# R7FA8M1AH register map
Vendor: Renesas; Series: RA8; File version: 1.2
CPU: CM85 r0p0, little endian, MPU, FPU, VTOR, 4 interrupt priority bits
Registers are 32-bit, read-write, reset 0x0 unless marked. A register's access mark holds for its fields unless they carry their own. Offsets are from the block's base; [hi:lo] are bit positions; {n}, {i} and the like mark numbered series; 'fields as' and 'values as' point back to an identical list.

## CANFD0 (part 1 of 2) — CANFD Module 0
Base 0x40380000
Same registers: CANFD1 0x40382000, CANFD0_NS 0x50380000, CANFD1_NS 0x50382000
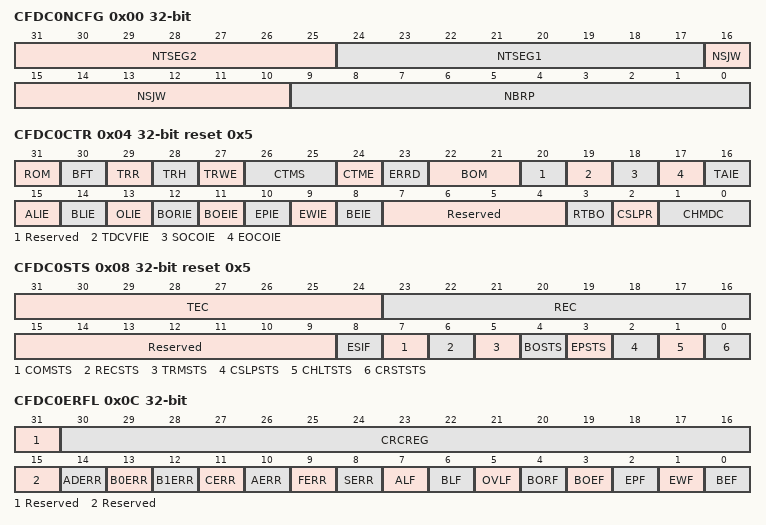
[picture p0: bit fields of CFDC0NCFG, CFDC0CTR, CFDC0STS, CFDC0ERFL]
0x00 CFDC0NCFG — Channel 0 Nominal Bitrate Configuration Register
  [31:25] NTSEG2 — Timing Segment 2
    1=2Tq; 2=3Tq; 3=4Tq; 126=127 Tq; 127=128 Tq
  [24:17] NTSEG1 — Timing Segment 1
    1=2Tq; 2=3Tq; 3=4Tq; 254=255 Tq; 255=256 Tq
  [16:10] NSJW — Resynchronization Jump Width
    {v}={v+1}Tq (v=0..3); 126=127 Tq; 127=128 Tq
  [9:0] NBRP — Channel Nominal Baud Rate Prescaler
0x04 CFDC0CTR reset 0x5 — Channel 0 Control Registers
  [31] ROM — Restricted Operation Mode
    0=Restricted Operation Mode disabled; 1=Restricted Operation Mode enabled
  [30] BFT — Bit Flip Test
    0=First data bit of reception stream not inverted; 1=First data bit of reception stream inverted
  [29] TRR — TEC/REC Reset
    0=Error counter normal operation; 1=Error counter reset
  [28] TRH — TEC/REC Hold
    0=Error counter normal operation; 1=Error counter frozen
  [27] TRWE — TEC/REC Write Enable
    0=Error Counter write disabled; 1=Error Counter write enabled
  [26:25] CTMS — Channel Test Mode Select
    0=Basic test mode; 1=Listen-Only mode; 2=Self test mode 0 (External Loop back mode); 3=Self test mode 1 (Internal Loop back mode)
  [24] CTME — Channel Test Mode Enable
    0=Channel Test Mode disabled; 1=Channel Test Mode enabled
  [23] ERRD — Channel Error Display
    0=Only the 1st set of error codes displayed; 1=Accumulated error codes displayed
  [22:21] BOM — Channel Bus-Off Mode
    0=Normal mode (comply with ISO 11898-1); 1=Entry to Halt Mode automatically at Bus-Off start; 2=Entry to Halt Mode automatically at Bus-Off end; 3=Entry to Halt Mode (during Bus-Off Recovery Period) by S/W
  [20] Reserved — This bit is read as 0. The write value should be 0.
  [19] TDCVFIE — Transceiver Delay Compensation Violation Interrupt enable
    0=Transceiver Delay Compensation Violation Interrupt disabled; 1=Transceiver Delay Compensation Violation Interrupt enabled
  [18] SOCOIE — Successful Occurrence Counter Overflow Interrupt enable
    0=Successful occurrence counter overflow interrupt disabled; 1=Successful occurrence counter overflow interrupt enabled
  [17] EOCOIE — Error occurrence counter overflow Interrupt enable
    0=Error occurrence counter overflow Interrupt disabled; 1=Error occurrence counter overflow Interrupt enabled
  [16] TAIE — Transmission abort Interrupt Enable
    0=TX abort Interrupt disabled; 1=TX abort Interrupt enabled
  [15] ALIE — Arbitration Lost Interrupt Enable
    0=Arbitration Lost Interrupt disabled; 1=Arbitration Lost Interrupt enabled
  [14] BLIE — Bus Lock Interrupt Enable
    0=Bus Lock Interrupt disabled; 1=Bus Lock Interrupt enabled
  [13] OLIE — Overload Interrupt Enable
    0=Overload Interrupt disabled; 1=Overload Interrupt enabled
  [12] BORIE — Bus-Off Recovery Interrupt Enable
    0=Bus-Off Recovery Interrupt disabled; 1=Bus-Off Recovery Interrupt enabled
  [11] BOEIE — Bus-Off Entry Interrupt Enable
    0=Bus-Off Entry Interrupt disabled; 1=Bus-Off Entry Interrupt enabled
  [10] EPIE — Error Passive Interrupt Enable
    0=Error Passive Interrupt disabled; 1=Error Passive Interrupt enabled
  [9] EWIE — Error Warning Interrupt Enable
    0=Error Warning Interrupt disabled; 1=Error Warning Interrupt enabled
  [8] BEIE — Bus Error Interrupt Enable
    0=Bus Error Interrupt disabled; 1=Bus Error Interrupt enabled
  [7:4] Reserved — These bits are read as 0000. The write value should be 0000.
  [3] RTBO — Return from Bus-Off
    0=Channel is not forced to return from Bus-Off; 1=Channel is forced to return from Bus-Off
  [2] CSLPR — Channel Sleep Request
    0=Channel Sleep Request disabled; 1=Channel Sleep Request enabled
  [1:0] CHMDC — Channel Mode Control
    0=Channel Operation Mode request; 1=Channel Reset request; 2=Channel Halt request; 3=Keep current value
0x08 CFDC0STS reset 0x5 — Channel 0 Status Registers
  [31:24] TEC — Transmission Error Count
  [23:16] REC ro — Reception Error Count
  [15:9] Reserved — These bits are read as 0000000. The write value should be 0000000.
  [8] ESIF — Error State Indication Flag
    0=No CAN-FD message has been received with the ESI flag was set; 1=At least 1 CAN-FD message was received where the ESI flag was set
  [7] COMSTS ro — Channel Communication Status
    0=Channel is not ready for communication; 1=Channel is ready for communication
  [6] RECSTS ro — Channel Receive Status
    0=Channel is not receiving; 1=Channel is receiving
  [5] TRMSTS ro — Channel Transmit Status
    0=Channel is not transmitting; 1=Channel is transmitting
  [4] BOSTS ro — Channel Bus-Off Status
    0=Channel not in Bus-Off state; 1=Channel in Bus-Off state
  [3] EPSTS ro — Channel Error Passive Status
    0=Channel not in Error Passive state; 1=Channel in Error Passive state
  [2] CSLPSTS ro — Channel SLEEP Status
    0=Channel not in Sleep Mode; 1=Channel in Sleep Mode
  [1] CHLTSTS ro — Channel HALT Status
    0=Channel not in Halt Mode; 1=Channel in Halt Mode
  [0] CRSTSTS ro — Channel RESET Status
    0=Channel not in Reset Mode; 1=Channel in Reset Mode
0x0C CFDC0ERFL — Channel 0 Error Flag Registers
  [31] Reserved — This bit is read as 0. The write value should be 0.
  [30:16] CRCREG ro — CRC Register value
  [15] Reserved — This bit is read as 0. The write value should be 0.
  [14] ADERR — Acknowledge Delimiter Error
    0=Channel Ack Del Error not detected; 1=Channel Ack Del Error detected
  [13] B0ERR — Bit 0 Error
    0=Channel Bit 0 Error not detected; 1=Channel Bit 0 Error detected
  [12] B1ERR — Bit 1 Error
    0=Channel Bit 1 Error not detected; 1=Channel Bit 1 Error detected
  [11] CERR — CRC Error
    0=Channel CRC Error not detected; 1=Channel CRC Error detected
  [10] AERR — Acknowledge Error
    0=Channel Ack Error not detected; 1=Channel Ack Error detected
  [9] FERR — Form Error
    0=Channel Form Error not detected; 1=Channel Form Error detected
  [8] SERR — Stuff Error
    0=Channel stuff Error not detected
  [7] ALF — Arbitration Lost Flag
    0=Channel Arbitration Lost not detected; 1=Channel Arbitration Lost detected
  [6] BLF — Bus Lock Flag
    0=Channel Bus Lock not detected; 1=Channel Bus Lock detected
  [5] OVLF — Overload Flag
    0=Channel Overload not detected; 1=Channel Overload detected
  [4] BORF — Bus-Off Recovery Flag
    0=Channel Bus-Off Recovery not detected; 1=Channel Bus-Off Recovery detected
  [3] BOEF — Bus-Off Entry Flag
    0=Channel Bus-Off Entry not detected; 1=Channel Bus-Off Entry detected
  [2] EPF — Error Passive Flag
    0=Channel Error Passive not detected; 1=Channel Error Passive detected
  [1] EWF — Error Warning Flag
    0=Channel Error Warning not detected; 1=Channel Error Warning detected
  [0] BEF — Bus Error Flag
    0=Channel Bus Error not detected; 1=Channel Bus Error detected
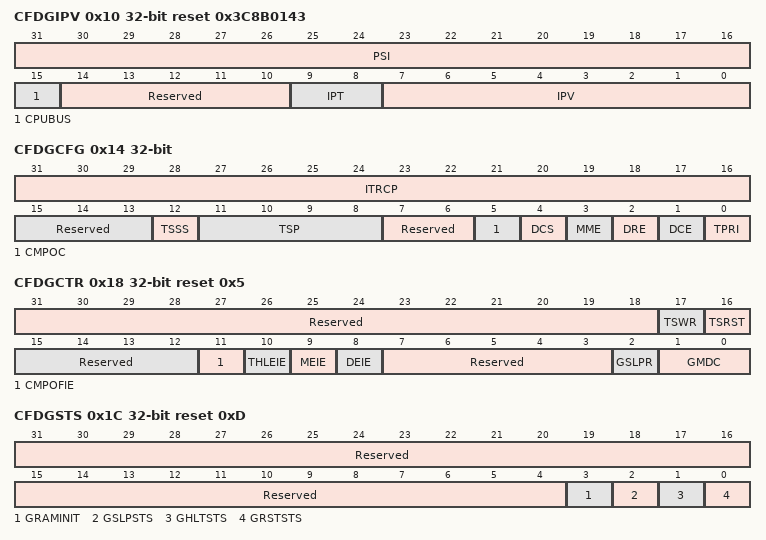
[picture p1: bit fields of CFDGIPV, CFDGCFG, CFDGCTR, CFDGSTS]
0x10 CFDGIPV ro reset 0x3C8B0143 — Global IP Version Register
  [31:16] PSI — Parameter Status Information
  [15] CPUBUS — CPU bus information
  [14:10] Reserved — These bits are read as 00000.
  [9:8] IPT — IP Type Release Number
  [7:0] IPV — IP Version Release Number
0x14 CFDGCFG — Global Configuration Register
  [31:16] ITRCP — Interval Timer Reference Clock Prescaler
  [15:13] Reserved — These bits are read as 000. The write value should be 000.
  [12] TSSS — Timestamp Source Select
    0=Source clock for Timestamp counter is peripheral clock; 1=Source clock for Timestamp counter is bit time clock
  [11:8] TSP — Timestamp Prescaler
    0=Timestamp Prescaler = 1; 1=Timestamp Prescaler = 2; 15=Timestamp Prescaler = 32768
  [7:6] Reserved — These bits are read as 00. The write value should be 00.
  [5] CMPOC — CAN-FD message Payload overflow configuration
    0=Message is rejected; 1=Message payload is cut to fit to configured message size
  [4] DCS — Data Link Controller Clock Select
    0=Internal clean clock; 1=External Clock source connected to clk_xincan pin
  [3] MME — Mirror Mode Enable
    0=Mirror Mode disabled; 1=Mirror Mode enabled
  [2] DRE — DLC Replacement Enable
    0=DLC replacement disabled; 1=DLC replacement enabled
  [1] DCE — DLC Check Enable
    0=DLC check disabled; 1=DLC check enabled
  [0] TPRI — Transmission Priority
    0=ID Priority; 1=Message Buffer Number Priority
0x18 CFDGCTR reset 0x5 — Global Control Register
  [31:18] Reserved — These bits are read as 00000000000000. The write value should be 00000000000000.
  [17] TSWR — Timestamp Write
    0=Timestamp write disabled; 1=Timestamp write enabled
  [16] TSRST — Timestamp Reset
    0=Timestamp not reset; 1=Timestamp reset
  [15:12] Reserved — These bits are read as 0000. The write value should be 0000.
  [11] CMPOFIE — CAN-FD message payload overflow Flag Interrupt enable
    0=CAN-FD message payload overflow Flag Interrupt Disabled; 1=CAN-FD message payload overflow Flag Interrupt Enabled
  [10] THLEIE — TX History List Entry Lost Interrupt Enable
    0=TX History List Entry Lost Interrupt Disabled; 1=TX History List Entry Lost Interrupt Enabled
  [9] MEIE — Message lost Error Interrupt Enable
    0=Message Lost Error Interrupt Disabled; 1=Message Lost Error Interrupt Enabled
  [8] DEIE — DLC check Interrupt Enable
    0=DLC check Interrupt Disabled; 1=DLC check Interrupt Enabled
  [7:3] Reserved — These bits are read as 00000. The write value should be 00000.
  [2] GSLPR — Global Sleep Request
    0=Global Sleep Request Disabled; 1=Global Sleep Request Enabled
  [1:0] GMDC — Global Mode Control
    0=Global Operation Mode Request; 1=Global Reset Mode Request; 2=Global Halt Mode Request; 3=Keep Current Value; 0=ID Priority; 1=Message Buffer Number Priority
0x1C CFDGSTS ro reset 0xD — Global Status Register
  [31:4] Reserved — These bits are read as 0000000000000000000000000000.
  [3] GRAMINIT — Global RAM Initialisation
    0=RAM initialisation is finished; 1=RAM initialisation ongoing
  [2] GSLPSTS — Global Sleep Status
    0=Not in Sleep Mode; 1=In Sleep Mode
  [1] GHLTSTS — Global Halt Status
    0=Not in Halt Mode; 1=In Halt Mode
  [0] GRSTSTS — Global Reset Status
    0=Not in Reset Mode; 1=In Reset Mode
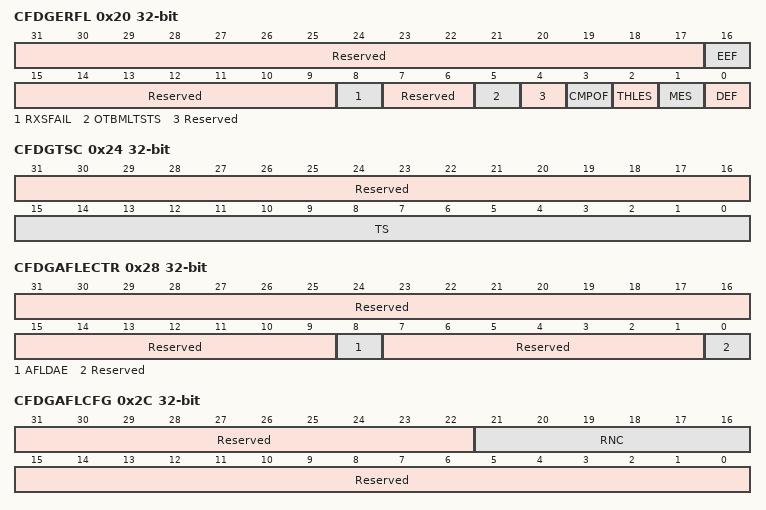
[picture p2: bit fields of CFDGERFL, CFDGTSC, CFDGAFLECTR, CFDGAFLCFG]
0x20 CFDGERFL — Global Error Flag Register
  [31:17] Reserved — These bits are read as 000000000000000. The write value should be 000000000000000.
  [16] EEF — ECC Error Flag
    0=ECC Error not detected during TX-SCAN; 1=ECC Error detected during TX-SCAN
  [15:9] Reserved — These bits are read as 0000000. The write value should be 0000000.
  [8] RXSFAIL — RX Scan Fail
    0=RX Scan fail not detected; 1=RX Scan fail detected
  [7:6] Reserved — These bits are read as 00. The write value should be 00.
  [5] OTBMLTSTS ro — OTB FIFO Message Lost Status
    0=Message lost Error not detected; 1=Message lost Error detected
  [4] Reserved — This bit is read as 0. The write value should be 0.
  [3] CMPOF — CAN-FD message payload overflow Flag
    0=CAN-FD message payload overflow not detected; 1=CAN-FD message payload overflow detected
  [2] THLES ro — TX History List Entry Lost Error Status
    0=TX History List Entry Lost Error not detected; 1=TX History List Entry Lost Error detected
  [1] MES ro — Message Lost Error Status
    values as OTBMLTSTS
  [0] DEF — DLC Error Flag
    1=DLC Error detected
0x24 CFDGTSC ro — Global Timestamp Counter Register
  [31:16] Reserved — These bits are read as 0000000000000000.
  [15:0] TS — Timestamp Value
0x28 CFDGAFLECTR — Global Acceptance Filter List Entry Control Register
  [31:9] Reserved — These bits are read as 00000000000000000000000. The write value should be 00000000000000000000000.
  [8] AFLDAE — Acceptance Filter List Data Access Enable
    0=Acceptance Filter List Data access disabled; 1=Acceptance Filter List Data access enabled
  [7:1] Reserved — These bits are read as 0000000. The write value should be 0000000.
  [0] Reserved — This bit is read as 0. The write value should be 0.
0x2C CFDGAFLCFG — Global Acceptance Filter List Configuration Register
  [31:22] Reserved — These bits are read as 0000000000. The write value should be 0000000000.
  [21:16] RNC — Rule Number
  [15:0] Reserved — These bits are read as 0000000000000000. The write value should be 0000000000000000.
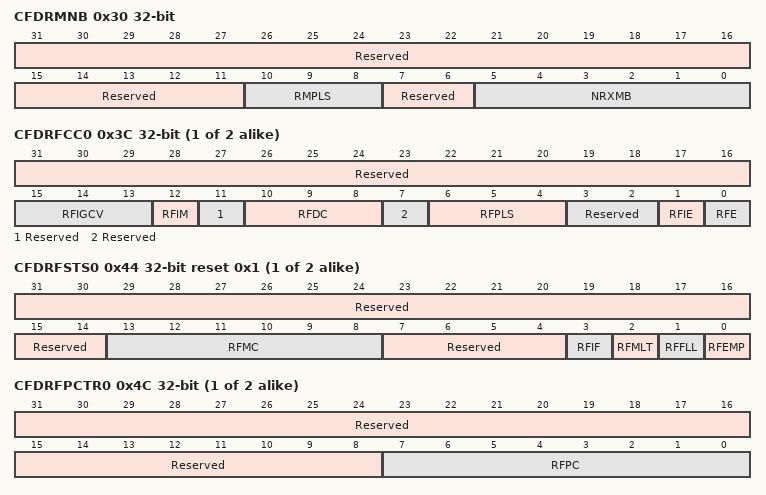
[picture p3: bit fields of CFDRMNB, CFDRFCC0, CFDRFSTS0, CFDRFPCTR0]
0x30 CFDRMNB — RX Message Buffer Number Register
  [31:11] Reserved — These bits are read as 000000000000000000000. The write value should be 000000000000000000000.
  [10:8] RMPLS — Reception Message Buffer Payload Data Size
    0=8 Bytes; 1=12 Bytes; 2=16 Bytes; 3=20 Bytes; 4=24 Bytes; 5=32 Bytes; 6=48 Bytes; 7=64 Bytes
  [7:6] Reserved — These bits are read as 00. The write value should be 00.
  [5:0] NRXMB — Number of RX Message Buffers
0x34 CFDRMND — RX Message Buffer New Data Register t(t=0)
  [31:0] RMNSu — RX Message Buffer New Data Status
    0=New Data not stored in corresponding RX Message Buffer; 1=New Data stored in corresponding RX Message Buffer
0x38 CFDRMIEC — RX Message Buffer Interrupt Enable Configuration Register
  [31:0] RMIE — RX Message Buffer Interrupt Enable
{0x3C+4i} CFDRFCC{i} (i=0..1) — RX FIFO Configuration / Control Registers {i}
  [31:16] Reserved — These bits are read as 0000000000000000. The write value should be 0000000000000000.
  [15:13] RFIGCV — RX FIFO Interrupt Generation Counter Value
    0=Interrupt generated when FIFO is 1/8th Full; 1=Interrupt generated when FIFO is 1/4th Full; 2=Interrupt generated when FIFO is 3/8th Full; 3=Interrupt generated when FIFO is 1/2 Full; 4=Interrupt generated when FIFO is 5/8th Full; 5=Interrupt generated when FIFO is 3/4th Full; 6=Interrupt generated when FIFO is 7/8th Full; 7=Interrupt generated when FIFO is Full
  [12] RFIM — RX FIFO Interrupt Mode
    0=Interrupt generated when RX FIFO counter reaches RFIGCV value from values smaller than RFIGCV; 1=Interrupt generated at the end of every received message storage
  [11] Reserved — This bit is read as 0. The write value should be 0.
  [10:8] RFDC — RX FIFO Depth Configuration
    0=FIFO Depth = 0 Messages; 1=FIFO Depth = 4 Messages; 2=FIFO Depth = 8 Messages; 3=FIFO Depth = 16 Messages; 4=FIFO Depth = 32 Messages; 5=FIFO Depth = 48 Messages
  [7] Reserved — This bit is read as 0. The write value should be 0.
  [6:4] RFPLS — Rx FIFO Payload Data Size configuration
    values as CFDRMNB.RMPLS
  [3:2] Reserved — These bits are read as 00. The write value should be 00.
  [1] RFIE — RX FIFO Interrupt Enable
    0=FIFO Interrupt generation disabled; 1=FIFO Interrupt generation enabled
  [0] RFE — RX FIFO Enable
    0=FIFO disabled; 1=FIFO enabled
{0x44+4i} CFDRFSTS{i} (i=0..1) reset 0x1 — RX FIFO Status Registers {i}
  [31:14] Reserved — These bits are read as 000000000000000000. The write value should be 000000000000000000.
  [13:8] RFMC ro — RX FIFO Message Count
  [7:4] Reserved — These bits are read as 0000. The write value should be 0000.
  [3] RFIF — RX FIFO Interrupt Flag
    0=FIFO Interrupt condition not satisfied; 1=FIFO Full interrupt condition satisfied
  [2] RFMLT — RX FIFO Message Lost
    0=No Message Lost in FIFO; 1=FIFO Message Lost
  [1] RFFLL ro — RX FIFO Full
    0=FIFO Not Full; 1=FIFO Full
  [0] RFEMP ro — RX FIFO Empty
    0=FIFO Not Empty; 1=FIFO Empty
{0x4C+4i} CFDRFPCTR{i} (i=0..1) — RX FIFO Pointer Control Registers {i}
  [31:8] Reserved — These bits are read as 000000000000000000000000. The write value should be 000000000000000000000000.
  [7:0] RFPC — RX FIFO Pointer Control
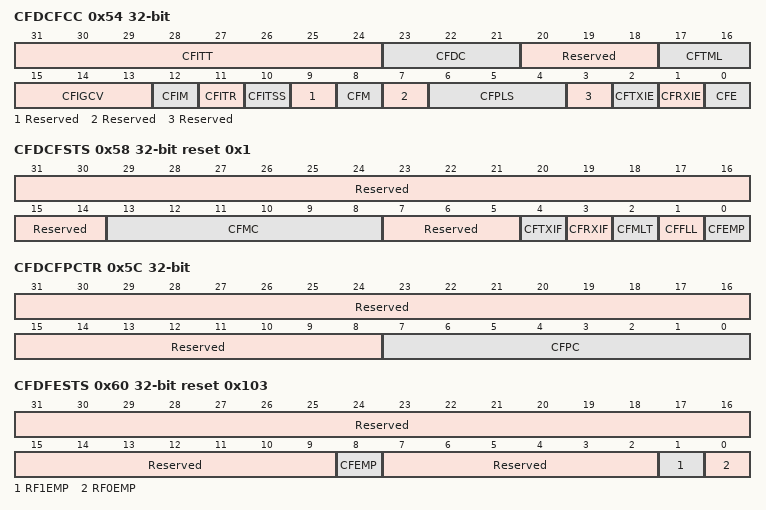
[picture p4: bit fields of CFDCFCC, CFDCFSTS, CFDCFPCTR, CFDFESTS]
0x54 CFDCFCC — Common FIFO Configuration / Control Registers
  [31:24] CFITT — Common FIFO Interval Transmission Time
  [23:21] CFDC — Common FIFO Depth Configuration
    0=FIFO Depth = 0 Messages; 1=FIFO Depth = 4 Messages; 2=FIFO Depth = 8 Messages; 3=FIFO Depth = 16 Messages; 4=FIFO Depth = 32 Messages; 5=FIFO Depth = 48 Messages; 6=FIFO Depth = Reserved; 7=FIFO Depth = Reserved
  [20:18] Reserved — These bits are read as 000. The write value should be 000.
  [17:16] CFTML — Common FIFO TX Message Buffer Link
  [15:13] CFIGCV — Common FIFO Interrupt Generation Counter Value
    values as CFDRFCC0.RFIGCV
  [12] CFIM — Common FIFO Interrupt Mode
  [11] CFITR — Common FIFO Interval Timer Resolution
    0=Reference Clock Period x1; 1=Reference Clock Period x10
  [10] CFITSS — Common FIFO Interval Timer Source Select
    0=Reference Clock (x1 / x10 period); 1=Bit Time Clock of related channel (FIFO is linked to fixed channel)
  [9] Reserved — This bit is read as 0. The write value should be 0.
  [8] CFM — Common FIFO Mode
    0=RX FIFO Mode; 1=TX FIFO Mode
  [7] Reserved — This bit is read as 0. The write value should be 0.
  [6:4] CFPLS — Common FIFO Payload Data size configuration
    0=8 Bytes; 7=64 Bytes
  [3] Reserved — This bit is read as 0. The write value should be 0.
  [2] CFTXIE — Common FIFO TX Interrupt Enable
    0=FIFO Interrupt generation disabled for Frame TX; 1=FIFO Interrupt generation enabled for Frame TX
  [1] CFRXIE — Common FIFO RX Interrupt Enable
    0=FIFO Interrupt generation disabled for Frame RX; 1=FIFO Interrupt generation enabled for Frame RX
  [0] CFE — Common FIFO Enable
    0=FIFO disabled; 1=FIFO enabled
0x58 CFDCFSTS reset 0x1 — Common FIFO Status Registers
  [31:14] Reserved — These bits are read as 000000000000000000. The write value should be 000000000000000000.
  [13:8] CFMC ro — Common FIFO Message Count
  [7:5] Reserved — These bits are read as 000. The write value should be 000.
  [4] CFTXIF — Common TX FIFO Interrupt Flag
    0=FIFO Interrupt condition not satisfied after Frame Transmission; 1=FIFO Interrupt condition satisfied after Frame Transmission
  [3] CFRXIF — Common RX FIFO Interrupt Flag
    0=FIFO Interrupt condition not satisfied after Frame Reception; 1=FIFO Interrupt condition satisfied after Frame Reception
  [2] CFMLT — Common FIFO Message Lost
    0=No Message Lost in FIFO; 1=FIFO Message Lost
  [1] CFFLL ro — Common FIFO Full
    0=FIFO Not Full; 1=FIFO Full
  [0] CFEMP ro — Common FIFO Empty
    0=FIFO Not Empty; 1=FIFO Empty
0x5C CFDCFPCTR — Common FIFO Pointer Control Registers
  [31:8] Reserved — These bits are read as 000000000000000000000000. The write value should be 000000000000000000000000.
  [7:0] CFPC wo — Common FIFO Pointer Control
0x60 CFDFESTS ro reset 0x103 — FIFO Empty Status Register
  [31:9] Reserved — These bits are read as 00000000000000000000000.
  [8] CFEMP — Common FIF0 Empty Status
  [7:2] Reserved — These bits are read as 000000.
  [1] RF1EMP — RX FIF0 1 Empty Status
    0=FIFO Not Empty; 1=FIFO Empty
  [0] RF0EMP — RX FIF0 0 Empty Status
    0=FIFO Not Empty; 1=FIFO Empty
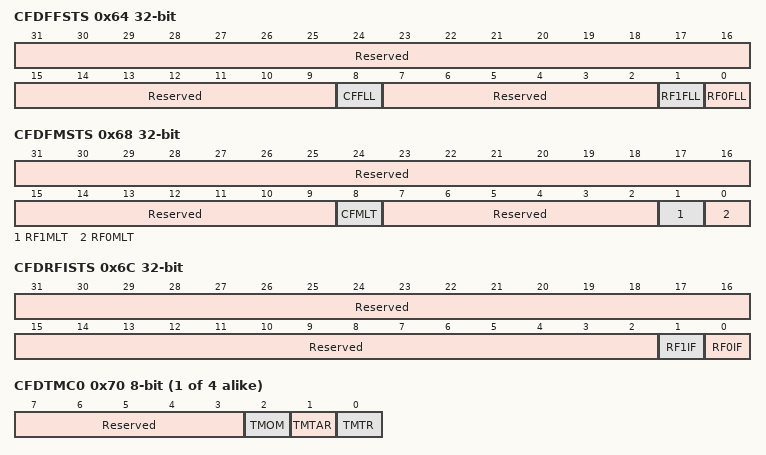
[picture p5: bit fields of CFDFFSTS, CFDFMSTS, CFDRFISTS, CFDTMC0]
0x64 CFDFFSTS ro — FIFO Full Status Register
  [31:9] Reserved — These bits are read as 00000000000000000000000.
  [8] CFFLL — Common FIF0 Full Status
    0=FIFO Not Empty; 1=FIFO Empty
  [7:2] Reserved — These bits are read as 000000.
  [1] RF1FLL — RX FIF0 1 Full Status
    0=FIFO Not Empty; 1=FIFO Empty
  [0] RF0FLL — RX FIF0 0 Full Status
    0=FIFO Not Empty; 1=FIFO Empty
0x68 CFDFMSTS ro — FIFO Message Lost Status Register
  [31:9] Reserved — These bits are read as 00000000000000000000000.
  [8] CFMLT — Common FIFO Msg Lost Status
    0=Corresponding FIFO Msg Lost flag not set; 1=Corresponding FIFO Msg Lost flag set
  [7:2] Reserved — These bits are read as 000000.
  [1] RF1MLT — RX FIFO 1 Msg Lost Status
    values as CFMLT
  [0] RF0MLT — RX FIFO 0 Msg Lost Status
    values as CFMLT
0x6C CFDRFISTS ro — RX FIFO Interrupt Flag Status Register
  [31:2] Reserved — These bits are read as 000000000000000000000000000000.
  [1] RF1IF — RX FIFO[1] Interrupt Flag Status
    0=Corresponding RX FIFO interrupt flag not set; 1=Corresponding RX FIFO interrupt flag set
  [0] RF0IF — RX FIFO[0] Interrupt Flag Status
    values as RF1IF
{0x70+i} CFDTMC{i} (i=0..3) 8-bit — TX Message Buffer Control Registers {i}
  [7:3] Reserved — These bits are read as 00000. The write value should be 00000.
  [2] TMOM — TX Message Buffer One-shot Mode
    0=TX Message Buffer not configured in one-shot mode; 1=TX Message Buffer configured in one-shot mode
  [1] TMTAR — TX Message Buffer Transmission abort Request
    0=TX Message Buffer transmission request abort not requested; 1=TX Message Buffer transmission request abort requested
  [0] TMTR — TX Message Buffer Transmission Request
    0=TX Message Buffer Transmission not requested; 1=TX Message Buffer Transmission requested
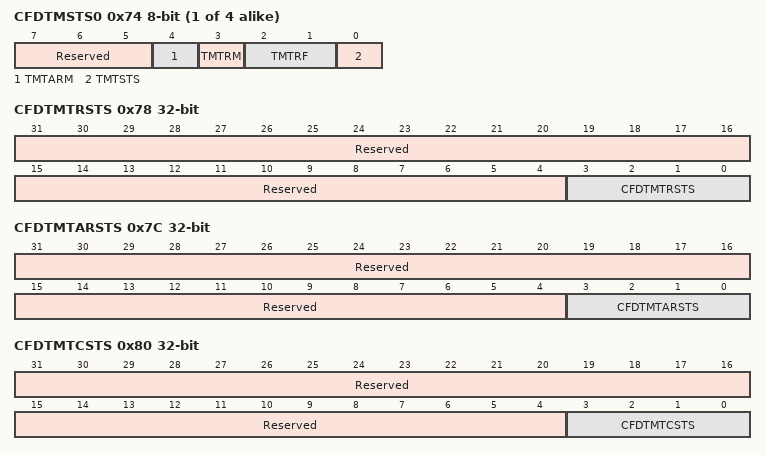
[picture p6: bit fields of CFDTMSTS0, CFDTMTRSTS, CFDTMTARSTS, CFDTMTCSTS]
{0x74+i} CFDTMSTS{i} (i=0..3) 8-bit — TX Message Buffer Status Registers {i}
  [7:5] Reserved — These bits are read as 000. The write value should be 000.
  [4] TMTARM ro — TX Message Buffer Transmission abort Request Mirrored
    values as CFDTMC0.TMTAR
  [3] TMTRM ro — TX Message Buffer Transmission Request Mirrored
    values as CFDTMC0.TMTR
  [2:1] TMTRF — TX Message Buffer Transmission Result Flag
    0=No Result; 1=Transmission aborted from the TX MB; 2=Transmission successful from the TX MB & Transmission abort was not requested; 3=Transmission successful from the TX MB & Transmission abort was requested
  [0] TMTSTS ro — TX Message Buffer Transmission Status
    0=No transmission ongoing; 1=Transmission ongoing
0x78 CFDTMTRSTS ro — TX Message Buffer Transmission Request Status Register
  [31:4] Reserved — These bits are read as 0000000000000000000000000000.
  [3:0] CFDTMTRSTS — TX Message Buffer Transmission Request Status
    0=Transmission not requested for corresponding TX Message Buffer; 1=Transmission requested for corresponding TX Message Buffer
0x7C CFDTMTARSTS ro — TX Message Buffer Transmission Abort Request Status Register
  [31:4] Reserved — These bits are read as 0000000000000000000000000000.
  [3:0] CFDTMTARSTS — TX Message Buffer Transmission abort Request Status
    0=Transmission abort not requested for corresponding TX Message Buffer; 1=Transmission abort requested for corresponding TX Message Buffer
0x80 CFDTMTCSTS ro — TX Message Buffer Transmission Completion Status Register
  [31:4] Reserved — These bits are read as 0000000000000000000000000000.
  [3:0] CFDTMTCSTS — TX Message Buffer Transmission Completion Status
    0=Transmission not complete for corresponding TX Message Buffer; 1=Transmission completed for corresponding TX Message Buffer
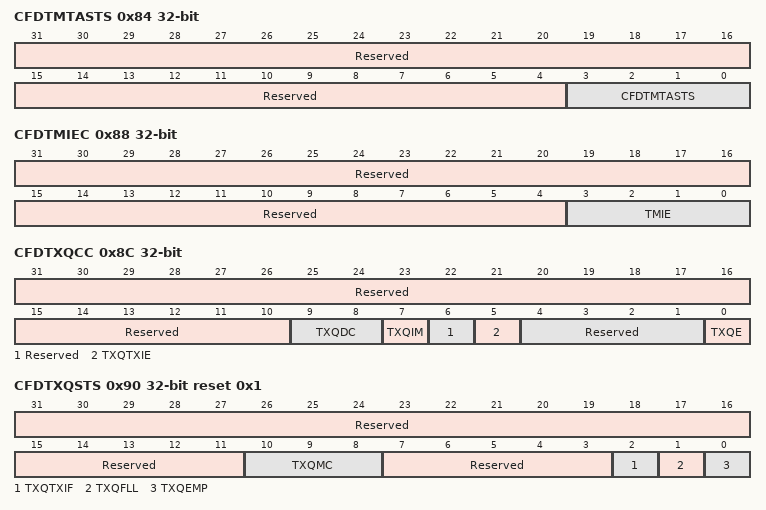
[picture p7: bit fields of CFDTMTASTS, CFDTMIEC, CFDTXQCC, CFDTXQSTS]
0x84 CFDTMTASTS ro — TX Message Buffer Transmission Abort Status Register
  [31:4] Reserved — These bits are read as 0000000000000000000000000000.
  [3:0] CFDTMTASTS — TX Message Buffer Transmission abort Status
    0=Transmission not aborted for corresponding TX Message Buffer; 1=Transmission aborted for corresponding TX Message Buffer
0x88 CFDTMIEC — TX Message Buffer Interrupt Enable Configuration Register
  [31:4] Reserved — These bits are read as 0000000000000000000000000000. The write value should be 0000000000000000000000000000.
  [3:0] TMIE — TX Message Buffer Interrupt Enable
    0=TX Message Buffer Interrupt disabled for corresponding TX message buffer; 1=TX Message Buffer Interrupt enabled for corresponding TX message buffer
0x8C CFDTXQCC — TX Queue Configuration / Control Registers
  [31:10] Reserved — These bits are read as 0000000000000000000000. The write value should be 0000000000000000000000.
  [9:8] TXQDC — TX Queue Depth Configuration
    0=0 messages; 2=3 messages; 3=4 messages
  [7] TXQIM — TX Queue Interrupt Mode
    0=when the last message is successfully transmitted; 1=At every successful transmission
  [6] Reserved — This bit is read as 0. The write value should be 0.
  [5] TXQTXIE — TX Queue TX Interrupt Enable
    0=TX Queue TX Interrupt disabled; 1=TX Queue TX Interrupt enabled
  [4:1] Reserved — These bits are read as 0000. The write value should be 0000.
  [0] TXQE — TX Queue Enable
    0=TX Queue disabled; 1=TX Queue enabled
0x90 CFDTXQSTS reset 0x1 — TX Queue Status Registers0
  [31:11] Reserved — These bits are read as 000000000000000000000. The write value should be 000000000000000000000.
  [10:8] TXQMC ro — TX Queue Message Count
  [7:3] Reserved — These bits are read as 00000. The write value should be 00000.
  [2] TXQTXIF — TX Queue TX Interrupt Flag
    0=TX Queue interrupt condition not satisfied after Frame TX; 1=TX Queue interrupt condition satisfied after Frame TX
  [1] TXQFLL ro — TX Queue Full
    0=TX Queue Not Full; 1=TX Queue Full
  [0] TXQEMP ro — TX Queue Empty
    0=TX Queue Not Empty; 1=TX Queue Empty
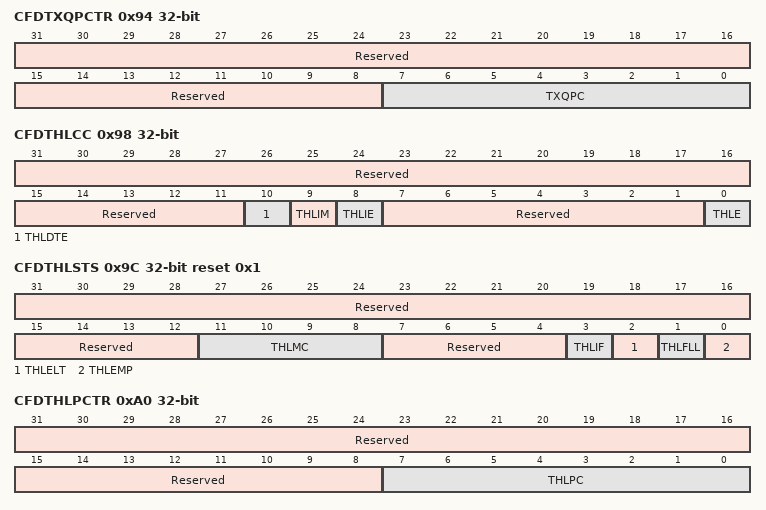
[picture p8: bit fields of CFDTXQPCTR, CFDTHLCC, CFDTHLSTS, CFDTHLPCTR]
0x94 CFDTXQPCTR wo — TX Queue Pointer Control Register
  [31:8] Reserved — The write value should be 000000000000000000000000.
  [7:0] TXQPC — TX Queue Pointer Control
0x98 CFDTHLCC — TX History List Configuration / Control Register
  [31:11] Reserved — These bits are read as 000000000000000000000. The write value should be 000000000000000000000.
  [10] THLDTE — TX History List Dedicated TX Enable
    0=TX FIFO + TX Queue (TX FIFO Only RL version); 1=Flat TX MB + TX FIFO + TX Queue (Flat TX MB + TX FIFO Only RL version)
  [9] THLIM — TX History List Interrupt Mode
    0=Interrupt generated if TX History List level reaches ¾ of the TX History List depth; 1=Interrupt generated for every successfully stored entry
  [8] THLIE — TX History List Interrupt Enable
    0=TX History List Interrupt disabled; 1=TX History List Interrupt enabled
  [7:1] Reserved — These bits are read as 0000000. The write value should be 0000000.
  [0] THLE — TX History List Enable
    0=TX History List disabled; 1=TX History List enabled
0x9C CFDTHLSTS reset 0x1 — TX History List Status Register
  [31:12] Reserved — These bits are read as 00000000000000000000. The write value should be 00000000000000000000.
  [11:8] THLMC ro — TX History List Message Count
  [7:4] Reserved — These bits are read as 0000. The write value should be 0000.
  [3] THLIF — TX History List Interrupt Flag
    0=TX History List Interrupt condition not satisfied; 1=TX History List Interrupt condition satisfied
  [2] THLELT — TX History List Entry Lost
    0=No Entry Lost in TX History List; 1=TX History List Entry Lost
  [1] THLFLL ro — TX History List Full
    0=TX History List Not Full; 1=TX History List Full
  [0] THLEMP ro — TX History List Empty
    0=TX History List Not Empty; 1=TX History List Empty
0xA0 CFDTHLPCTR wo — TX History List Pointer Control Registers
  [31:8] Reserved — The write value should be 000000000000000000000000.
  [7:0] THLPC — TX History List Pointer Control
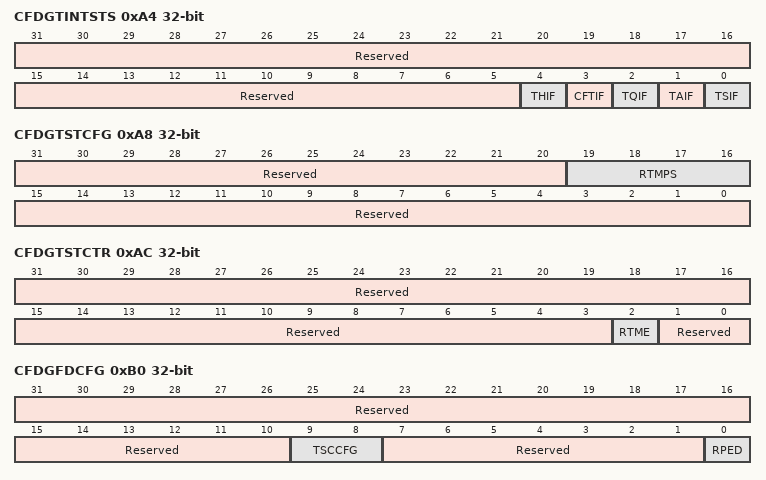
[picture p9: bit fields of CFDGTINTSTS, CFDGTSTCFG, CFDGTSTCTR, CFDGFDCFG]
0xA4 CFDGTINTSTS ro — Global TX Interrupt Status Register
  [31:5] Reserved — These bits are read as 000000000000000000000000000.
  [4] THIF — TX History List Interrupt Channel
    0=Channel n TX History List Interrupt flag not set; 1=Channel n TX History List Interrupt flag set
  [3] CFTIF — COM FIFO TX/GW Mode Interrupt Flag Channel
    0=Channel n COM FIFO TX/GW mode Interrupt flag not set; 1=Channel n COM FIFO TX/GW mode Interrupt flag set
  [2] TQIF — TX Queue Interrupt Flag Channel
    0=Channel n TX Queue Interrupt flag not set; 1=Channel n TX Queue Interrupt flag set
  [1] TAIF — TX Abort Interrupt Flag Channel
    0=Channel n TX abort Interrupt flag not set; 1=Channel n TX abort Interrupt flag set
  [0] TSIF — TX Successful Interrupt Flag Channel
    0=Channel n TX Successful completion Interrupt flag not set; 1=Channel n TX Successful completion Interrupt flag set
0xA8 CFDGTSTCFG — Global Test Configuration Register
  [31:20] Reserved — These bits are read as 000000000000. The write value should be 000000000000.
  [19:16] RTMPS — RAM Test Mode Page Select
  [15:0] Reserved — These bits are read as 0000000000000000. The write value should be 0000000000000000.
0xAC CFDGTSTCTR — Global Test Control Register
  [31:3] Reserved — These bits are read as 00000000000000000000000000000. The write value should be 00000000000000000000000000000.
  [2] RTME — RAM Test Mode Enable
    0=RAM Test Mode disabled; 1=RAM Test Mode enabled
  [1:0] Reserved — These bits are read as 00. The write value should be 00.
0xB0 CFDGFDCFG — Global FD configuration register
  [31:10] Reserved — These bits are read as 0000000000000000000000. The write value should be 0000000000000000000000.
  [9:8] TSCCFG — Timestamp capture configuration
    0=Timestamp capture at the sample point of SOF (start of frame); 1=Timestamp capture at frame valid indication; 2=Timestamp capture at the sample point of RES bit
  [7:1] Reserved — These bits are read as 0000000. The write value should be 0000000.
  [0] RPED — RES bit Protocol exception disable
    0=Protocol exception event detection enabled; 1=Protocol exception event detection disabled
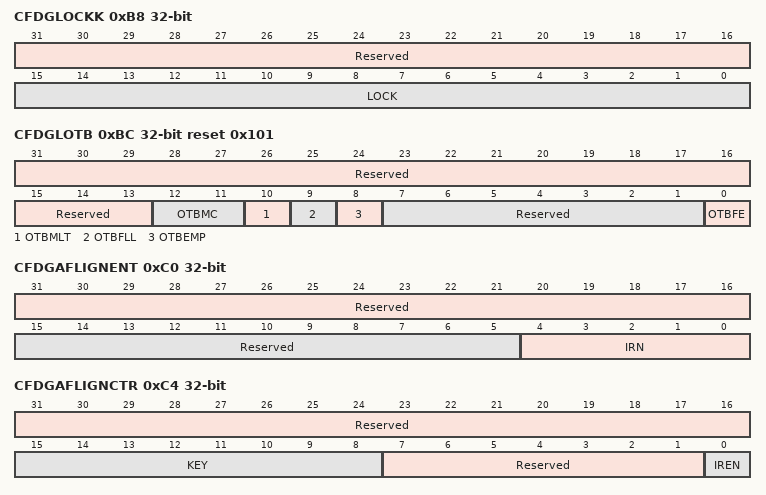
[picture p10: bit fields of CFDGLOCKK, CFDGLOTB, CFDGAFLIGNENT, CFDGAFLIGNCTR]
0xB8 CFDGLOCKK wo — Global Lock Key Register
  [31:16] Reserved — The write value should be 0000000000000000.
  [15:0] LOCK — Lock Key
0xBC CFDGLOTB reset 0x101 — Global OTB FIFO Configuration / Status Register
  [31:13] Reserved — These bits are read as 0000000000000000000. The write value should be 0000000000000000000.
  [12:11] OTBMC ro — OTB FIFO Message Count
  [10] OTBMLT — OTB FIFO Message Lost
    0=No Message Lost in FIFO; 1=FIFO Message Lost
  [9] OTBFLL ro — OTB FIFO Full
    0=FIFO Not Full; 1=FIFO Full
  [8] OTBEMP ro — OTB FIFO Empty
    0=FIFO Not Empty; 1=FIFO Empty
  [7:1] Reserved — These bits are read as 0000000. The write value should be 0000000.
  [0] OTBFE — OTB FIFO Enable
    0=FIFO disabled; 1=FIFO enabled
0xC0 CFDGAFLIGNENT — Global AFL Ignore Entry Register
  [31:16] Reserved — These bits are read as 0000000000000000. The write value should be 0000000000000000.
  [15:5] Reserved — These bits are read as 00000000000. The write value should be 00000000000.
  [4:0] IRN — Ignore Rule Number
0xC4 CFDGAFLIGNCTR — Global AFL Ignore Control Register
  [31:16] Reserved — These bits are read as 0000000000000000. The write value should be 0000000000000000.
  [15:8] KEY wo — Key code
  [7:1] Reserved — These bits are read as 0000000. The write value should be 0000000.
  [0] IREN — Ignore Rule Enable
    0=AFL rule number does not ignore; 1=AFL rule number ignores
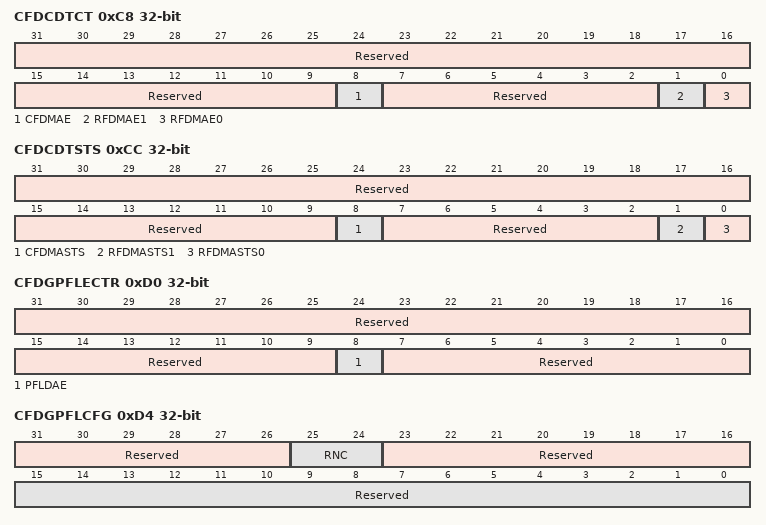
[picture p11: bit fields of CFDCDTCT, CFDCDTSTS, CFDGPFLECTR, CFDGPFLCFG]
0xC8 CFDCDTCT — DMA Transfer Control Register
  [31:9] Reserved — These bits are read as 00000000000000000000000. The write value should be 00000000000000000000000.
  [8] CFDMAE — DMA Transfer Enable for Common FIFO 0 of channel 0
    0=DMA Transfer Request disabled for channel n; 1=DMA Transfer Request enabled for channel n
  [7:2] Reserved — These bits are read as 000000. The write value should be 000000.
  [1] RFDMAE1 — DMA Transfer Enable for RXFIFO 1
    0=DMA Transfer Request disabled; 1=DMA Transfer Request enabled
  [0] RFDMAE0 — DMA Transfer Enable for RXFIFO 0
    values as RFDMAE1
0xCC CFDCDTSTS — DMA Transfer Status Register
  [31:9] Reserved — These bits are read as 00000000000000000000000. The write value should be 00000000000000000000000.
  [8] CFDMASTS ro — DMA Transfer Status only for Common FIFO 0 of channel 0
    0=DMA transfer stopped; 1=DMA transfer ongoing
  [7:2] Reserved — These bits are read as 000000. The write value should be 000000.
  [1] RFDMASTS1 ro — DMA Transfer Status for RX FIFO 1
    0=DMA transfer stopped; 1=DMA transfer ongoing
  [0] RFDMASTS0 ro — DMA Transfer Status for RX FIFO 0
    0=DMA transfer stopped; 1=DMA transfer ongoing
0xD0 CFDGPFLECTR — Global Pretended Network Filter List Entry control Register
  [31:9] Reserved — These bits are read as 00000000000000000000000. The write value should be 00000000000000000000000.
  [8] PFLDAE — Pretended Network Filter List Data Access Enable
    0=Pretended Network Filter List Data access disabled; 1=Pretended Network Filter List Data access enabled
  [7:0] Reserved — These bits are read as 00000000. The write value should be 00000000.
0xD4 CFDGPFLCFG — Global Pretended Network Filter List configuration Register
  [31:26] Reserved — These bits are read as 000000. The write value should be 000000.
  [25:24] RNC — Rule Number
  [23:16] Reserved — These bits are read as 00000000. The write value should be 00000000.
  [15:0] Reserved — These bits are read as 0000000000000000. The write value should be 0000000000000000.
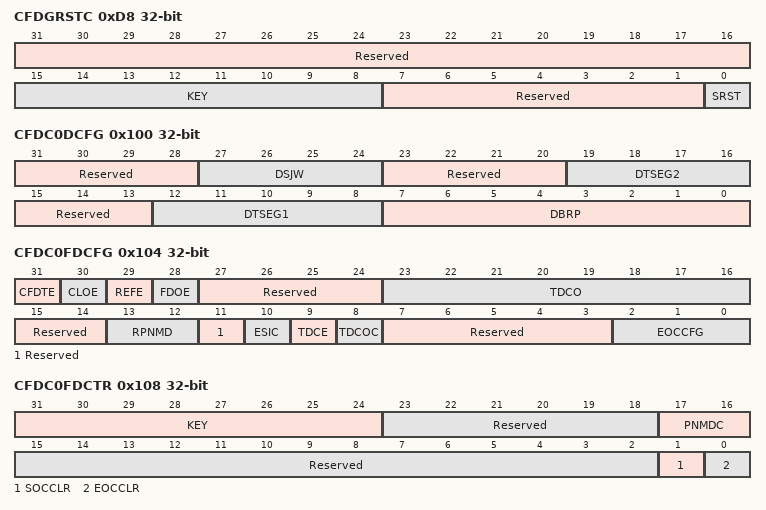
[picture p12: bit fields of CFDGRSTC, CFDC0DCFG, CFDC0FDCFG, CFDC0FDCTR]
0xD8 CFDGRSTC — Global Reset Control Register
  [31:16] Reserved — These bits are read as 0000000000000000. The write value should be 0000000000000000.
  [15:8] KEY wo — Key code
  [7:1] Reserved — These bits are read as 0000000. The write value should be 0000000.
  [0] SRST — SW reset
    0=normal state; 1=SW reset state
0x100 CFDC0DCFG — Channel 0 Data Bitrate Configuration Register
  [31:28] Reserved — These bits are read as 0000. The write value should be 0000.
  [27:24] DSJW — Resynchronization Jump Width
    0=1 Tq; 1=2 Tq; 14=15 Tq; 15=16 Tq
  [23:20] Reserved — These bits are read as 0000. The write value should be 0000.
  [19:16] DTSEG2 — Timing Segment 2
    1=2 Tq; 14=15 Tq; 15=16 Tq
  [15:13] Reserved — These bits are read as 000. The write value should be 000.
  [12:8] DTSEG1 — Timing Segment 1
    1=2 Tq; 30=31 Tq; 31=32 Tq
  [7:0] DBRP — Channel Data Baud Rate Prescaler
0x104 CFDC0FDCFG — Channel 0 CAN-FD Configuration Register
  [31] CFDTE — CAN-FD Tolerance enable
    0=CAN-FD Tolerance mode disabled; 1=CAN-FD Tolerance mode enabled
  [30] CLOE — Classical CAN only enable
    0=Classical only mode disabled; 1=Classical only mode enabled
  [29] REFE — RX edge filter enable
    0=RX edge filter disabled; 1=RX edge filter enabled
  [28] FDOE — FD only enable
    0=FD only mode disabled; 1=FD only mode enabled
  [27:24] Reserved — These bits are read as 0000. The write value should be 0000.
  [23:16] TDCO — Transceiver Delay Compensation Offset
  [15:14] Reserved — These bits are read as 00. The write value should be 00.
  [13:12] RPNMD — Return Pretended Network Filter Mode
    0=Return to Acceptance Filter Mode; 1=Return to Pretended Network Filter ID only and Acceptance Filter Mode; 2=Return to Pretended Network Filter and Acceptance Filter Mode; 3=Return to Pretended Network Filter Mode (Not return)
  [11] Reserved — This bit is read as 0. The write value should be 0.
  [10] ESIC — Error State Indication Configuration
    0=The ESI bit in the frame will be representing the Error state of the node itself; 1=The ESI bit in the frame will be representing the Error state of message buffer if the node itself is not in error passive. If the node is in Error Passive then the ESI bit will be driven by the node itself
  [9] TDCE — Transceiver Delay Compensation Enable
    0=Transceiver Delay Compensation disabled; 1=Transceiver Delay Compensation enabled
  [8] TDCOC — Transceiver Delay Compensation Offset Configuration
    0=Measured + offset; 1=offset only
  [7:3] Reserved — These bits are read as 00000. The write value should be 00000.
  [2:0] EOCCFG — Error Occurrence Counter Configuration
    0=All Transmitter or Receiver CAN Frames; 1=All Transmitter CAN Frames; 2=All Receiver CAN Frames; 4=Only Transmitter or Receiver CAN-FD Data-Phase (fast bits); 5=Only Transmitter CAN-FD Data-Phase (fast bits); 6=Only Receiver CAN-FD Data-Phase (fast bits)
0x108 CFDC0FDCTR — Channel 0 CAN-FD Control Register
  [31:24] KEY wo — Key code
  [23:18] Reserved — These bits are read as 000000. The write value should be 000000.
  [17:16] PNMDC — Pretended Network Filter Mode Control
  [15:2] Reserved — These bits are read as 00000000000000. The write value should be 00000000000000.
  [1] SOCCLR — Successful Occurrence Counter Clear
    0=No Successful Occurrence Counter clear; 1=Clear Successful Occurrence Counter
  [0] EOCCLR — Error Occurrence Counter Clear
    0=No Error Occurrence Counter clear; 1=Clear Error Occurrence Counter
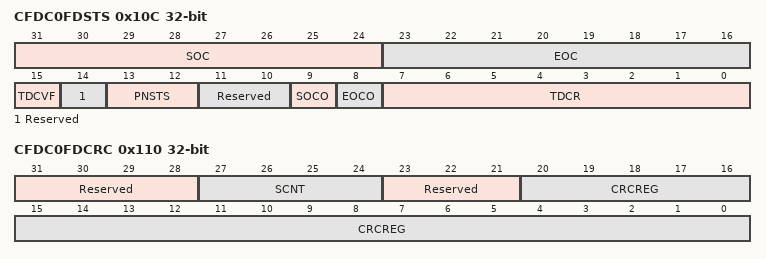
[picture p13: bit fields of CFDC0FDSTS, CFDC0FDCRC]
0x10C CFDC0FDSTS — Channel 0 CAN-FD Status Register
  [31:24] SOC ro — Successful occurrence counter register
  [23:16] EOC ro — Error occurrence counter register
  [15] TDCVF — Transceiver Delay Compensation Violation Flag
    0=Transceiver Delay Compensation Violation has not occurred; 1=Transceiver Delay Compensation Violation has occurred
  [14] Reserved — This bit is read as 0. The write value should be 0.
  [13:12] PNSTS ro — Pretended Network Filter State
    0=Acceptance Filter Mode; 1=Pretended Network Filter Mode; 2=Pretended Network Filter and Acceptance Filter Mode; 3=Pretended Network Filter ID only and Acceptance Filter Mode
  [11:10] Reserved — These bits are read as 00. The write value should be 00.
  [9] SOCO — Successful occurrence counter overflow
    0=Successful occurrence counter has not overflowed; 1=Successful occurrence counter has overflowed
  [8] EOCO — Error occurrence counter overflow
    0=Error occurrence counter has not overflowed; 1=Error occurrence counter has overflowed
  [7:0] TDCR ro — Transceiver Delay Compensation Result
    values as CFDC0FDCTR.EOCCLR
0x110 CFDC0FDCRC — Channel 0 CAN-FD CRC Register
  [31:28] Reserved — These bits are read as 0000. The write value should be 0000.
  [27:24] SCNT ro — Stuff bit count
  [23:21] Reserved — These bits are read as 000. The write value should be 000.
  [20:0] CRCREG ro — CRC Register value
    values as CFDC0FDCTR.EOCCLR
